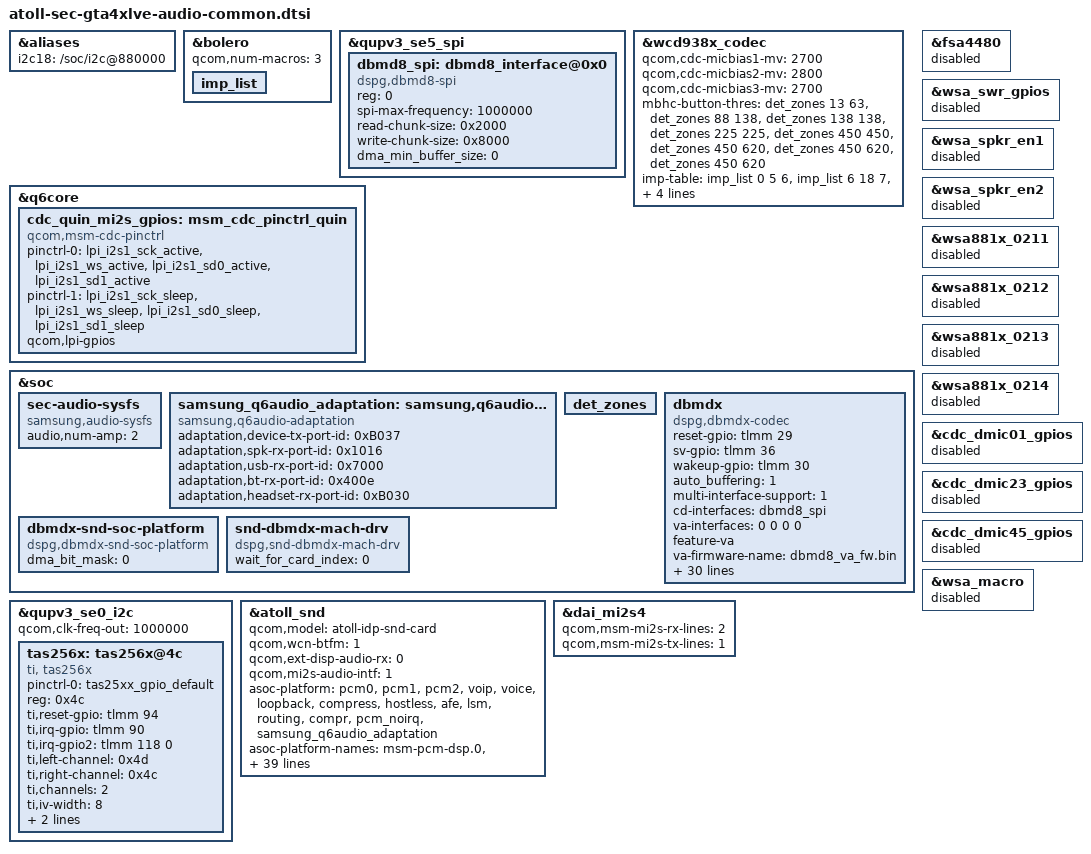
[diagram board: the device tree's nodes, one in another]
/* Copyright (c) 2019, The Linux Foundation. All rights reserved.
 *
 * This program is free software; you can redistribute it and/or modify
 * it under the terms of the GNU General Public License version 2 and
 * only version 2 as published by the Free Software Foundation.
 *
 * This program is distributed in the hope that it will be useful,
 * but WITHOUT ANY WARRANTY; without even the implied warranty of
 * MERCHANTABILITY or FITNESS FOR A PARTICULAR PURPOSE.  See the
 * GNU General Public License for more details.
 */

&aliases {
	i2c18 = "/soc/i2c@880000";
};

&bolero {
	qcom,num-macros = <3>;
	imp_list: imp_list {
		#list-imp-cells = <3>;
	};
};

&qupv3_se5_spi {
	status = "okay";
	dbmd8_spi:dbmd8_interface@0x0  {
		compatible = "dspg,dbmd8-spi";
		reg = <0>;
		spi-max-frequency = <1000000>;
		read-chunk-size  = <0x2000> ;
		write-chunk-size = <0x8000> ;
		dma_min_buffer_size = <0>;
	};
};

&wcd938x_codec {
	qcom,cdc-micbias1-mv = <2700>;
	qcom,cdc-micbias2-mv = <2800>;
	qcom,cdc-micbias3-mv = <2700>;
	mbhc-button-thres = <&det_zones 13 63>,
		 <&det_zones 88 138>,
		 <&det_zones 138 138>,
		 <&det_zones 225 225>,
		 <&det_zones 450 450>,
		 <&det_zones 450 620>,
		 <&det_zones 450 620>,
		 <&det_zones 450 620>;
	imp-table = <&imp_list 0 5 6>,
			 <&imp_list 6 18 7>,
			 <&imp_list 19 33 6>,
			 <&imp_list 34 100 6>,
			 <&imp_list 101 160 10>,
			 <&imp_list 161 400 11>,
			 <&imp_list 401 2000 11>,
			 <&imp_list 2001 0x7fffffff 6>;
};

&q6core {
	cdc_quin_mi2s_gpios: msm_cdc_pinctrl_quin {
		compatible = "qcom,msm-cdc-pinctrl";
		pinctrl-names = "aud_active", "aud_sleep";
		pinctrl-0 = <&lpi_i2s1_sck_active &lpi_i2s1_ws_active
				 &lpi_i2s1_sd0_active &lpi_i2s1_sd1_active>;
		pinctrl-1 = <&lpi_i2s1_sck_sleep &lpi_i2s1_ws_sleep
				 &lpi_i2s1_sd0_sleep &lpi_i2s1_sd1_sleep>;
		qcom,lpi-gpios;
	};
};

&soc {
	sec-audio-sysfs {
		compatible = "samsung,audio-sysfs";
		status = "okay";
		audio,num-amp = <2>;
	};

	samsung_q6audio_adaptation: samsung,q6audio-adaptation {
		compatible = "samsung,q6audio-adaptation";
		adaptation,device-tx-port-id = <0xB037>;
		adaptation,spk-rx-port-id = <0x1016>;
		adaptation,usb-rx-port-id = <0x7000>;
		adaptation,bt-rx-port-id = <0x400e>;
		adaptation,headset-rx-port-id = <0xB030>;
	};

	det_zones: det_zones {
		#list-det-cells = <2>;
	};

	dbmdx {
		status = "okay";
		compatible = "dspg,dbmdx-codec";
		reset-gpio = <&tlmm 29 0>;
		sv-gpio = <&tlmm 36 0>;
		wakeup-gpio = <&tlmm 30 0>;
		auto_buffering = <1>;
		multi-interface-support = <1>;
		cd-interfaces = <&dbmd8_spi>;
		va-interfaces = <0 0 0 0>;
		feature-va; /* enable VA */
		va-firmware-name = "dbmd8_va_fw.bin";
		va-asrp-params-firmware-name = "dbmd8_va_asrp_fw.bin";
		va-config =	<0x80000000
				0x80000000
				0x80000000
				0x80290020
				0x801b0020
				0x80093004
				0x802210E1
				0x8033006E
				0x80159494
				0x80230000
				0x801A0001
				0x8010d004
				0x8aab0040
				0x800C7530
				0x80000000
				0x80000000
				0x80000000
				0x80000000>;
				/* 2MIC_NR_DET 1MIC_DET 2MIC_NR_STREAM 2MIC_NONR_STREAM IDLE */
		va-ns-config = <0x80000000 0x80000000 0x80000000 0x80000000 0x80000000
				0x80250200 0x80250200 0x80250200 0x80250200 0x80250200
				0x80240200 0x80240200 0x80240200 0x80240200 0x80240200
				0x803D0109 0x80000000 0x803D0109 0x80000000 0x80000000
				0x803E0000 0x80000000 0x803E0000 0x80000000 0x8aab0014
				0x80340243 0x80340040 0x80340243 0x80340040 0x8013FFFF
				0x8aab0014 0x8aab0014 0x8aab0014 0x8aab0014 0x8aab0014
				0x80110E10 0x8013FFF0 0x80110E10 0x8013FFF0 0x80340000
				0x80111EEE 0x80040000 0x80111EEE 0x80040000 0x8aab0014
				0x80112EEE 0x8016FF18 0x80112EE2 0x8016FF18 0x80000000
				0x80113EEE 0x80000000 0x80113EEE 0x80000000 0x80000000
				0x80114EEE 0x80000000 0x80114EEE 0x80000000 0x80000000
				0x80115EE2 0x80000000 0x80115EE2 0x80000000 0x80000000
				0x80116EEE 0x80000000 0x80116EEE 0x80000000 0x80000000
				0x80117EEE 0x80000000 0x80117EEE 0x80000000 0x80000000
				0x8013FF20 0x80000000 0x8013FFF2 0x80000000 0x80000000
				0x80040000 0x80000000 0x80040000 0x80000000 0x80000000
				0x8016FF18 0x80000000 0x8016FF12 0x80000000 0x80000000
				0x80000000 0x80000000 0x80000000 0x80000000 0x80000000
				0x80000000 0x80000000 0x80000000 0x80000000 0x80000000
				0x80000000 0x80000000 0x80000000 0x80000000 0x80000000
				0x80000000 0x80000000 0x80000000 0x80000000 0x80000000
				0x80000000 0x80000000 0x80000000 0x80000000 0x80000000>;


		va-speeds = <0x0000 460800  0 1000000
			     0x0000 2000000 0 3000000
			     0x0000 3000000 0 5000000>;
		va-mic-config = <0x868 0x0167 0x8>;
		va-mic-mode = <2>;

		master-clk-rate = <32768>;
		/* constant-clk-rate = <32768>; */
		firmware_id = <0xdbd8>;
		use_gpio_for_wakeup = <1>; /* Use wakeup gpio */
		wakeup_set_value = <0>;  /* Value to write to wakeup gpio */
		auto_detection = <1>;
		detection_buffer_channels = <1>;
		min_samples_chunk_size = <128>;
		pcm_streaming_mode = <1>;
		boot_options = <0x220>; /* Verify chip id */
		send_uevent_on_detection = <1>;
		send_uevent_after_buffering = <0>;
		detection_after_buffering = <0>;
		va_backlog_length = <1802>;
		va_backlog_length_okg = <1000>;
		amodel_options = <0x1c>;
		va_ns_supported = <1>;
		va_ns-num_of_configs = <5>;
		mic_config_source = <0>;
		wait_for_card_index = <0>;	/* Defer loading support to compile as module */
		retrigger_interval_sec = <600>;
	};

	dbmdx-snd-soc-platform {
		compatible = "dspg,dbmdx-snd-soc-platform";
		dma_bit_mask = <0>; /* DMA bit mask value will be default and not configured if 0*/
	};

	snd-dbmdx-mach-drv {
		compatible = "dspg,snd-dbmdx-mach-drv";
		wait_for_card_index = <0>;	/* Defer loading support to compile as module */
	};
};

&qupv3_se0_i2c {
	status = "okay";
	qcom,clk-freq-out = <1000000>;

	tas256x:tas256x@4c {
		status = "okay";
		#sound-dai-cells = <0>;
		compatible = "ti, tas256x";
		pinctrl-names = "default";
		pinctrl-0 = <&tas25xx_gpio_default>;
		reg = <0x4c>;
		ti,reset-gpio = <&tlmm 94 0>;
		ti,irq-gpio = <&tlmm 90 0>;
		ti,irq-gpio2 = <&tlmm 118 0>;
		ti,left-channel = <0x4d>;
		ti,right-channel = <0x4c>;
		ti,channels = <2>; /* channel number */
		ti,iv-width = <8>;
		ti,vbat-mon = <1>;
		ti,port_id = <0x1016>; /* Rx port ID use for Qcom platform */
	};
};

&atoll_snd {
	qcom,model = "atoll-idp-snd-card";
	qcom,wcn-btfm = <1>;
	qcom,ext-disp-audio-rx = <0>;
	qcom,mi2s-audio-intf = <1>;
	asoc-platform = <&pcm0>, <&pcm1>, <&pcm2>, <&voip>, <&voice>,
			<&loopback>, <&compress>, <&hostless>,
			<&afe>, <&lsm>, <&routing>, <&compr>,
			<&pcm_noirq>, <&samsung_q6audio_adaptation>;
	asoc-platform-names = "msm-pcm-dsp.0", "msm-pcm-dsp.1",
			"msm-pcm-dsp.2", "msm-voip-dsp",
			"msm-pcm-voice", "msm-pcm-loopback",
			"msm-compress-dsp", "msm-pcm-hostless",
			"msm-pcm-afe", "msm-lsm-client",
			"msm-pcm-routing", "msm-compr-dsp",
			"msm-pcm-dsp-noirq", "q6audio-adaptation";
	qcom,audio-routing =
		"AMIC1", "MIC BIAS1",
		"MIC BIAS1", "Analog Mic1",
		"AMIC2", "MIC BIAS2",
		"MIC BIAS2", "Analog Mic2",
		"AMIC3", "MIC BIAS3",
		"MIC BIAS3", "Analog Mic3",
		"AMIC4", "MIC BIAS3",
		"MIC BIAS3", "Analog Mic4",
		"AMIC5", "MIC BIAS4",
		"MIC BIAS4", "Analog Mic5",
		"IN1_HPHL", "HPHL_OUT",
		"IN2_HPHR", "HPHR_OUT",
		"TX SWR_ADC0", "ADC1_OUTPUT",
		"TX SWR_ADC1", "ADC2_OUTPUT",
		"TX SWR_ADC2", "ADC3_OUTPUT",
		"TX SWR_ADC3", "ADC4_OUTPUT",
		"RX_TX DEC0_INP", "TX DEC0 MUX",
		"RX_TX DEC1_INP", "TX DEC1 MUX",
		"RX_TX DEC2_INP", "TX DEC2 MUX",
		"RX_TX DEC3_INP", "TX DEC3 MUX",
		"VA_AIF1 CAP", "VA_SWR_CLK",
		"VA_AIF2 CAP", "VA_SWR_CLK",
		"VA_AIF3 CAP", "VA_SWR_CLK",
		"VA SWR_ADC0", "ADC1_OUTPUT",
		"VA SWR_ADC1", "ADC2_OUTPUT",
		"VA SWR_ADC2", "ADC3_OUTPUT",
		"VA SWR_ADC3", "ADC4_OUTPUT";

	qcom,msm-mbhc-hs-mic-max-threshold-mv = <9999>;
	qcom,msm-mbhc-hs-mic-min-threshold-mv = <640>;
	qcom,cdc-dmic01-gpios = <>;
	qcom,cdc-dmic23-gpios = <>;
	qcom,cdc-dmic45-gpios = <>;
	qcom,quin-mi2s-gpios = <&cdc_quin_mi2s_gpios>;
	asoc-codec  = <&stub_codec>, <&bolero>;
	asoc-codec-names = "msm-stub-codec.1", "bolero_codec";
	qcom,wsa-max-devs = <0>;
	qcom,wsa-devs = <0>;
	qcom,msm_audio_ssr_devs = <&audio_apr>, <&q6core>,
				  <&lpi_tlmm>, <&bolero>;
	fsa4480-i2c-handle = <>;
	qcom,fm-lna-gpios = <>;
	qcom,msm-mbhc-gnd-det = <0>;
};

&dai_mi2s4 {
	qcom,msm-mi2s-rx-lines = <2>;
	qcom,msm-mi2s-tx-lines = <1>;
};

&fsa4480 {
	status = "disabled";
};
&wsa_swr_gpios {
	status = "disabled";
};
&wsa_spkr_en1 {
	status = "disabled";
};
&wsa_spkr_en2 {
	status = "disabled";
};
&wsa881x_0211 {
	status = "disabled";
};
&wsa881x_0212 {
	status = "disabled";
};
&wsa881x_0213 {
	status = "disabled";
};
&wsa881x_0214 {
	status = "disabled";
};
&cdc_dmic01_gpios {
	status = "disabled";
};
&cdc_dmic23_gpios {
	status = "disabled";
};
&cdc_dmic45_gpios {
	status = "disabled";
};
&wsa_swr_gpios {
	status = "disabled";
};
&wsa_macro {
	status = "disabled";
};
